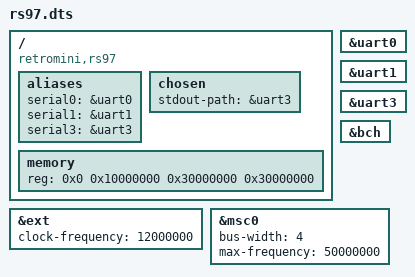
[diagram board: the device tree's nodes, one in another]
/dts-v1/;

#include "jz4760.dtsi"

/ {
	compatible = "retromini,rs97", "ingenic,jz4760";

	aliases {
		serial0 = &uart0;
		serial1 = &uart1;
		serial3 = &uart3;
	};

	chosen {
		stdout-path = &uart3;
	};

	memory {
		device_type = "memory";
		reg = <0x0 0x10000000
		       0x30000000 0x30000000>;
	};
};

&ext {
	clock-frequency = <12000000>;
};

&uart0 {
	status = "okay";
};

&uart1 {
	status = "okay";
};

&uart3 {
	status = "okay";
};

&bch {
	status = "okay";
};

&msc0 {
	bus-width = <4>;
	max-frequency = <50000000>;
	status = "okay";
};
